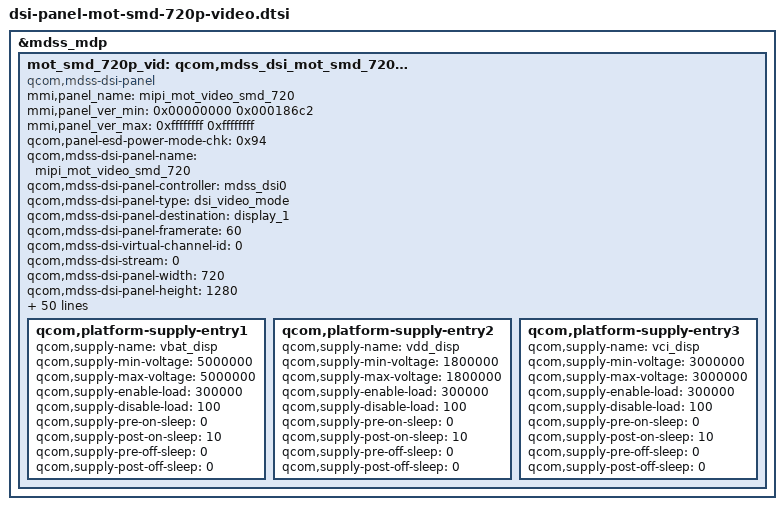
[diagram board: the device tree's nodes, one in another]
/* Copyright (c) 2012-2013, The Linux Foundation. All rights reserved.
 * Copyright (c) 2013 Motorola Mobility LLC
 *
 * This program is free software; you can redistribute it and/or modify
 * it under the terms of the GNU General Public License version 2 and
 * only version 2 as published by the Free Software Foundation.
 *
 * This program is distributed in the hope that it will be useful,
 * but WITHOUT ANY WARRANTY; without even the implied warranty of
 * MERCHANTABILITY or FITNESS FOR A PARTICULAR PURPOSE.  See the
 * GNU General Public License for more details.
 */

&mdss_mdp {
	mot_smd_720p_vid: qcom,mdss_dsi_mot_smd_720p_video {
		compatible = "qcom,mdss-dsi-panel";

		mmi,panel_name = "mipi_mot_video_smd_720";
		mmi,panel_ver_min = <0x00000000 0x000186c2>;
		mmi,panel_ver_max = <0xffffffff 0xffffffff>;
		qcom,panel-esd-power-mode-chk = <0x94>;

		qcom,mdss-dsi-panel-name = "mipi_mot_video_smd_720";
		qcom,mdss-dsi-panel-controller = <&mdss_dsi0>;
		qcom,mdss-dsi-panel-type = "dsi_video_mode";
		qcom,mdss-dsi-panel-destination = "display_1";
		qcom,mdss-dsi-panel-framerate = <60>;
		qcom,mdss-dsi-virtual-channel-id = <0>;
		qcom,mdss-dsi-stream = <0>;
		qcom,mdss-dsi-panel-width = <720>;
		qcom,mdss-dsi-panel-height = <1280>;
		qcom,mdss-pan-physical-width-dimension = <56>;
		qcom,mdss-pan-physical-height-dimension = <99>;
		qcom,mdss-dsi-h-front-porch = <144>;
		qcom,mdss-dsi-h-back-porch = <32>;
		qcom,mdss-dsi-h-pulse-width = <12>;
		qcom,mdss-dsi-h-sync-skew = <0>;
		qcom,mdss-dsi-v-back-porch = <3>;
		qcom,mdss-dsi-v-front-porch = <9>;
		qcom,mdss-dsi-v-pulse-width = <4>;
		qcom,mdss-dsi-h-left-border = <0>;
		qcom,mdss-dsi-h-right-border = <0>;
		qcom,mdss-dsi-v-top-border = <0>;
		qcom,mdss-dsi-v-bottom-border = <0>;
		qcom,mdss-dsi-bpp = <24>;
		qcom,mdss-dsi-underflow-color = <0xff>;
		qcom,mdss-dsi-border-color = <0>;

		qcom,mdss-dsi-tune-h-front-porch = <62>;
		qcom,mdss-dsi-tune-h-back-porch = <62>;
		qcom,mdss-dsi-tune-h-pulse-width = <8>;
		qcom,mdss-dsi-tune-v-back-porch = <15>;
		qcom,mdss-dsi-tune-v-front-porch = <15>;
		qcom,mdss-dsi-tune-v-pulse-width = <1280>;

		qcom,mdss-dsi-on-command = [
				05 01 00 00 78 00 02 11 00	/* exit sleep mode */
				39 01 00 00 01 00 03 f0 5a 5a	/* unlock_lvl_2 */
				39 01 00 00 01 00 03 f1 5a 5a	/* unlock_lvl_mtp */
				39 01 00 00 01 00 03 fc 5a 5a	/* unlock_lvl_3 */
				15 01 00 00 01 00 02 f2 05	/* set video mode */
				15 01 00 00 01 00 02 35 00	/* enable_te */
				39 01 00 00 01 00 02 53 20	/* disp_ctrl */
				15 01 00 00 01 00 02 51 7f	/* brightness_ctrl */
				39 01 00 00 01 00 02 55 00	/* acl_enable_disable_settings */
				39 01 00 00 01 00 05		/* set window size normal_col */
				2a 00 00 02 cf
				39 01 00 00 01 00 05		/* set window size normal_row */
				2b 00 00 04 ff
				29 01 00 00 00 00 02 29 00];	/* display on */

		qcom,mdss-dsi-off-command = [
				05 01 00 00 0a 00 02 28 00];	/* display_off */

		qcom,mdss-dsi-on-command-state = "dsi_lp_mode";
		qcom,mdss-dsi-off-command-state = "dsi_hs_mode";
		qcom,mdss-dsi-h-sync-pulse = <0>;
		qcom,mdss-dsi-traffic-mode = "non_burst_sync_event";
		qcom,mdss-dsi-bllp-eof-power-mode;
		qcom,mdss-dsi-bllp-power-mode;
		qcom,mdss-dsi-lane-0-state;
		qcom,mdss-dsi-lane-1-state;
		qcom,mdss-dsi-lane-2-state;
		qcom,mdss-dsi-lane-3-state;
		qcom,mdss-dsi-panel-timings = [b0 23 1b 00 94 93 1e 25 15 03 04 00];
		qcom,mdss-dsi-t-clk-post = <0x04>;
		qcom,mdss-dsi-t-clk-pre = <0x1b>;
		qcom,mdss-dsi-bl-min-level = <1>;
		qcom,mdss-dsi-bl-max-level = <4095>;
		qcom,mdss-dsi-dma-trigger = "trigger_sw";
		qcom,mdss-dsi-mdp-trigger = "none";
		qcom,mdss-dsi-bl-pmic-control-type = "bl_ctrl_wled";

		qcom,mdss-dsi-esd-det-mode = <1>;

		qcom,panel-en-reset-sequence = <1 11>;
		qcom,panel-dis-reset-sequence = <0 3>;
		qcom,platform-supply-entry1 {
			qcom,supply-name = "vbat_disp";
			qcom,supply-min-voltage = <5000000>;
			qcom,supply-max-voltage = <5000000>;
			qcom,supply-enable-load = <300000>;
			qcom,supply-disable-load = <100>;
			qcom,supply-pre-on-sleep = <0>;
			qcom,supply-post-on-sleep = <10>;
			qcom,supply-pre-off-sleep = <0>;
			qcom,supply-post-off-sleep = <0>;
		};
		qcom,platform-supply-entry2 {
			qcom,supply-name = "vdd_disp";
			qcom,supply-min-voltage = <1800000>;
			qcom,supply-max-voltage = <1800000>;
			qcom,supply-enable-load = <300000>;
			qcom,supply-disable-load = <100>;
			qcom,supply-pre-on-sleep = <0>;
			qcom,supply-post-on-sleep = <10>;
			qcom,supply-pre-off-sleep = <0>;
			qcom,supply-post-off-sleep = <0>;
		};
		qcom,platform-supply-entry3 {
			qcom,supply-name = "vci_disp";
			qcom,supply-min-voltage = <3000000>;
			qcom,supply-max-voltage = <3000000>;
			qcom,supply-enable-load = <300000>;
			qcom,supply-disable-load = <100>;
			qcom,supply-pre-on-sleep = <0>;
			qcom,supply-post-on-sleep = <10>;
			qcom,supply-pre-off-sleep = <0>;
			qcom,supply-post-off-sleep = <0>;
		};
	};
};
